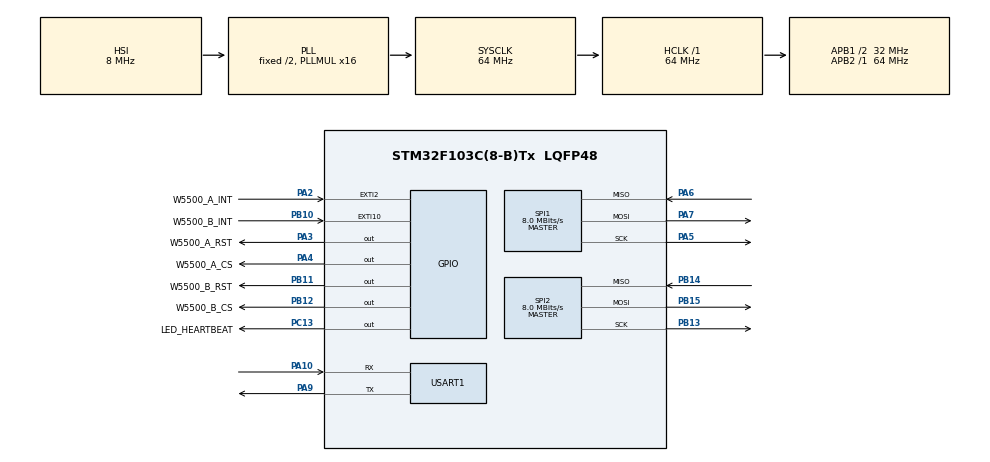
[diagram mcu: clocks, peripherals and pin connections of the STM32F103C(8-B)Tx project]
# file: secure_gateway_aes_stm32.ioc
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Dma.Request0=SPI1_RX
Dma.Request1=SPI1_TX
Dma.Request2=SPI2_RX
Dma.Request3=SPI2_TX
Dma.SPI1_RX.0.Direction=DMA_PERIPH_TO_MEMORY
Dma.SPI1_RX.0.Instance=DMA1_Channel2
Dma.SPI1_RX.0.MemDataAlignment=DMA_MDATAALIGN_BYTE
Dma.SPI1_RX.0.MemInc=DMA_MINC_ENABLE
Dma.SPI1_RX.0.Mode=DMA_NORMAL
Dma.SPI1_RX.0.PeriphDataAlignment=DMA_PDATAALIGN_BYTE
Dma.SPI1_RX.0.PeriphInc=DMA_PINC_DISABLE
Dma.SPI1_RX.0.Priority=DMA_PRIORITY_LOW
Dma.SPI1_TX.1.Direction=DMA_MEMORY_TO_PERIPH
Dma.SPI1_TX.1.Instance=DMA1_Channel3
Dma.SPI1_TX.1.MemDataAlignment=DMA_MDATAALIGN_BYTE
Dma.SPI1_TX.1.MemInc=DMA_MINC_ENABLE
Dma.SPI1_TX.1.Mode=DMA_NORMAL
Dma.SPI1_TX.1.PeriphDataAlignment=DMA_PDATAALIGN_BYTE
Dma.SPI1_TX.1.PeriphInc=DMA_PINC_DISABLE
Dma.SPI1_TX.1.Priority=DMA_PRIORITY_LOW
Dma.SPI2_RX.2.Direction=DMA_PERIPH_TO_MEMORY
Dma.SPI2_RX.2.Instance=DMA1_Channel4
Dma.SPI2_RX.2.MemDataAlignment=DMA_MDATAALIGN_BYTE
Dma.SPI2_RX.2.MemInc=DMA_MINC_ENABLE
Dma.SPI2_RX.2.Mode=DMA_NORMAL
Dma.SPI2_RX.2.PeriphDataAlignment=DMA_PDATAALIGN_BYTE
Dma.SPI2_RX.2.PeriphInc=DMA_PINC_DISABLE
Dma.SPI2_RX.2.Priority=DMA_PRIORITY_LOW
Dma.SPI2_TX.3.Direction=DMA_MEMORY_TO_PERIPH
Dma.SPI2_TX.3.Instance=DMA1_Channel5
Dma.SPI2_TX.3.MemDataAlignment=DMA_MDATAALIGN_BYTE
Dma.SPI2_TX.3.MemInc=DMA_MINC_ENABLE
Dma.SPI2_TX.3.Mode=DMA_NORMAL
Dma.SPI2_TX.3.PeriphDataAlignment=DMA_PDATAALIGN_BYTE
Dma.SPI2_TX.3.PeriphInc=DMA_PINC_DISABLE
Dma.SPI2_TX.3.Priority=DMA_PRIORITY_LOW
FREERTOS.INCLUDE_vTaskDelayUntil=1
FREERTOS.Tasks01=defaultTask,0,256,StartDefaultTask,Default,NULL,Dynamic,NULL,NULL
FREERTOS.configCHECK_FOR_STACK_OVERFLOW=2
FREERTOS.configMAX_PRIORITIES=6
FREERTOS.configUSE_COUNTING_SEMAPHORES=1
IWDG.Prescaler=IWDG_PRESCALER_16
IWDG.Reload=1249
Mcu.Family=STM32F1
Mcu.Name=STM32F103C(8-B)Tx
Mcu.Package=LQFP48
NVIC.DMA1_Channel2_IRQn=true\:6\:0\:true\:false\:true\:true\:false\:true\:true
NVIC.DMA1_Channel3_IRQn=true\:6\:0\:true\:false\:true\:true\:false\:true\:true
NVIC.DMA1_Channel4_IRQn=true\:6\:0\:true\:false\:true\:true\:false\:true\:true
NVIC.DMA1_Channel5_IRQn=true\:6\:0\:true\:false\:true\:true\:false\:true\:true
NVIC.EXTI15_10_IRQn=true\:6\:0\:true\:false\:true\:true\:true\:true\:true
NVIC.EXTI2_IRQn=true\:6\:0\:true\:false\:true\:true\:true\:true\:true
NVIC.PriorityGroup=NVIC_PRIORITYGROUP_4
NVIC.TIM4_IRQn=true\:15\:0\:false\:false\:true\:false\:false\:true\:true
NVIC.TimeBase=TIM4_IRQn
NVIC.TimeBaseIP=TIM4
PA10.Mode=Asynchronous
PA10.Signal=USART1_RX
PA13.Mode=Serial_Wire
PA13.Signal=SYS_JTMS-SWDIO
PA14.Mode=Serial_Wire
PA14.Signal=SYS_JTCK-SWCLK
PA2.GPIO_Label=W5500_A_INT
PA2.GPIO_ModeDefaultEXTI=GPIO_MODE_IT_FALLING
PA2.GPIO_PuPd=GPIO_PULLUP
PA2.Signal=GPXTI2
PA3.GPIO_Label=W5500_A_RST
PA3.PinState=GPIO_PIN_SET
PA3.Signal=GPIO_Output
PA4.GPIO_Label=W5500_A_CS
PA4.GPIO_Speed=GPIO_SPEED_FREQ_HIGH
PA4.PinState=GPIO_PIN_SET
PA4.Signal=GPIO_Output
PA5.Mode=Full_Duplex_Master
PA5.Signal=SPI1_SCK
PA6.Mode=Full_Duplex_Master
PA6.Signal=SPI1_MISO
PA7.Mode=Full_Duplex_Master
PA7.Signal=SPI1_MOSI
PA9.Mode=Asynchronous
PA9.Signal=USART1_TX
PB10.GPIO_Label=W5500_B_INT
PB10.GPIO_ModeDefaultEXTI=GPIO_MODE_IT_FALLING
PB10.GPIO_PuPd=GPIO_PULLUP
PB10.Signal=GPXTI10
PB11.GPIO_Label=W5500_B_RST
PB11.PinState=GPIO_PIN_SET
PB11.Signal=GPIO_Output
PB12.GPIO_Label=W5500_B_CS
PB12.GPIO_Speed=GPIO_SPEED_FREQ_HIGH
PB12.PinState=GPIO_PIN_SET
PB12.Signal=GPIO_Output
PB13.Mode=Full_Duplex_Master
PB13.Signal=SPI2_SCK
PB14.Mode=Full_Duplex_Master
PB14.Signal=SPI2_MISO
PB15.Mode=Full_Duplex_Master
PB15.Signal=SPI2_MOSI
PC13-TAMPER-RTC.GPIO_Label=LED_HEARTBEAT
PC13-TAMPER-RTC.PinState=GPIO_PIN_SET
PC13-TAMPER-RTC.Signal=GPIO_Output
ProjectManager.HeapSize=0x200
ProjectManager.StackSize=0x400
ProjectManager.TargetToolchain=STM32CubeIDE
RCC.AHBFreq_Value=64000000
RCC.APB1CLKDivider=RCC_HCLK_DIV2
RCC.APB1Freq_Value=32000000
RCC.APB1TimFreq_Value=64000000
RCC.APB2Freq_Value=64000000
RCC.APB2TimFreq_Value=64000000
RCC.HCLKFreq_Value=64000000
RCC.PLLMUL=RCC_PLL_MUL16
RCC.SYSCLKFreq_VALUE=64000000
RCC.SYSCLKSource=RCC_SYSCLKSOURCE_PLLCLK
RCC.USBFreq_Value=64000000
SPI1.BaudRatePrescaler=SPI_BAUDRATEPRESCALER_8
SPI1.CalculateBaudRate=8.0 MBits/s
SPI1.Direction=SPI_DIRECTION_2LINES
SPI1.Mode=SPI_MODE_MASTER
SPI1.VirtualType=VM_MASTER
SPI2.BaudRatePrescaler=SPI_BAUDRATEPRESCALER_4
SPI2.CalculateBaudRate=8.0 MBits/s
SPI2.Direction=SPI_DIRECTION_2LINES
SPI2.Mode=SPI_MODE_MASTER
SPI2.VirtualType=VM_MASTER
USART1.VirtualMode=VM_ASYNC
VP_FREERTOS_VS_CMSIS_V1.Mode=CMSIS_V1
VP_IWDG_VS_IWDG.Mode=IWDG_Activate
VP_SYS_VS_tim4.Mode=TIM4
board=custom

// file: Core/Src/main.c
/* USER CODE BEGIN Header */
/**
  ******************************************************************************
  * @file           : main.c
  * @brief          : Main program body
  ******************************************************************************
  * @attention
  *
  * Copyright (c) 2026 STMicroelectronics.
  * All rights reserved.
  *
  * This software is licensed under terms that can be found in the LICENSE file
  * in the root directory of this software component.
  * If no LICENSE file comes with this software, it is provided AS-IS.
  *
  ******************************************************************************
  */
/* USER CODE END Header */
#include "main.h"
#include "cmsis_os.h"
#include "dma.h"
#include "iwdg.h"
#include "spi.h"
#include "usart.h"
#include "gpio.h"

void SystemClock_Config(void);
void MX_FREERTOS_Init(void);

int main(void)
{

  /* MCU Configuration--------------------------------------------------------*/

  /* Reset of all peripherals, Initializes the Flash interface and the Systick. */
  HAL_Init();

  /* Configure the system clock */
  SystemClock_Config();

  /* Initialize all configured peripherals */
  MX_GPIO_Init();
  MX_DMA_Init();
  MX_SPI1_Init();
  MX_SPI2_Init();
  MX_USART1_UART_Init();
  MX_IWDG_Init();

  /* Call init function for freertos objects (in cmsis_os2.c) */
  MX_FREERTOS_Init();

  /* Start scheduler */
  osKernelStart();

  /* We should never get here as control is now taken by the scheduler */

  /* Infinite loop */
  while (1)
  {

  }
}

void SystemClock_Config(void)
{
  RCC_OscInitTypeDef RCC_OscInitStruct = {0};
  RCC_ClkInitTypeDef RCC_ClkInitStruct = {0};

  /** Initializes the RCC Oscillators according to the specified parameters
  * in the RCC_OscInitTypeDef structure.
  */
  RCC_OscInitStruct.OscillatorType = RCC_OSCILLATORTYPE_HSI|RCC_OSCILLATORTYPE_LSI;
  RCC_OscInitStruct.HSIState = RCC_HSI_ON;
  RCC_OscInitStruct.HSICalibrationValue = RCC_HSICALIBRATION_DEFAULT;
  RCC_OscInitStruct.LSIState = RCC_LSI_ON;
  RCC_OscInitStruct.PLL.PLLState = RCC_PLL_ON;
  RCC_OscInitStruct.PLL.PLLSource = RCC_PLLSOURCE_HSI_DIV2;
  RCC_OscInitStruct.PLL.PLLMUL = RCC_PLL_MUL16;
  if (HAL_RCC_OscConfig(&RCC_OscInitStruct) != HAL_OK)
  {
    Error_Handler();
  }

  /** Initializes the CPU, AHB and APB buses clocks
  */
  RCC_ClkInitStruct.ClockType = RCC_CLOCKTYPE_HCLK|RCC_CLOCKTYPE_SYSCLK
                              |RCC_CLOCKTYPE_PCLK1|RCC_CLOCKTYPE_PCLK2;
  RCC_ClkInitStruct.SYSCLKSource = RCC_SYSCLKSOURCE_PLLCLK;
  RCC_ClkInitStruct.AHBCLKDivider = RCC_SYSCLK_DIV1;
  RCC_ClkInitStruct.APB1CLKDivider = RCC_HCLK_DIV2;
  RCC_ClkInitStruct.APB2CLKDivider = RCC_HCLK_DIV1;

  if (HAL_RCC_ClockConfig(&RCC_ClkInitStruct, FLASH_LATENCY_2) != HAL_OK)
  {
    Error_Handler();
  }
}

void HAL_TIM_PeriodElapsedCallback(TIM_HandleTypeDef *htim)
{
  if (htim->Instance == TIM4)
  {
    HAL_IncTick();
  }
}

void Error_Handler(void)
{
  __disable_irq();
  while (1)
  {
  }
}

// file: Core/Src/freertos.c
/* USER CODE BEGIN Header */
/**
  ******************************************************************************
  * File Name          : freertos.c
  * Description        : Code for freertos applications
  ******************************************************************************
  * @attention
  *
  * Copyright (c) 2026 STMicroelectronics.
  * All rights reserved.
  *
  * This software is licensed under terms that can be found in the LICENSE file
  * in the root directory of this software component.
  * If no LICENSE file comes with this software, it is provided AS-IS.
  *
  ******************************************************************************
  */
/* USER CODE END Header */

#include "FreeRTOS.h"
#include "task.h"
#include "main.h"
#include "cmsis_os.h"

/* USER CODE BEGIN Includes */
#include "app_main.h"
#include "bsp_gpio.h"
#include "log_service.h"
#include <stdbool.h>
#include "bsp_w5500.h"
#include "net_service.h"
/* USER CODE END Includes */

osThreadId defaultTaskHandle;

void StartDefaultTask(void const * argument);

void MX_FREERTOS_Init(void); /* (MISRA C 2004 rule 8.1) */

/* GetIdleTaskMemory prototype (linked to static allocation support) */
void vApplicationGetIdleTaskMemory( StaticTask_t **ppxIdleTaskTCBBuffer, StackType_t **ppxIdleTaskStackBuffer, uint32_t *pulIdleTaskStackSize );

/* Hook prototypes */
void vApplicationStackOverflowHook(xTaskHandle xTask, signed char *pcTaskName);

/* USER CODE BEGIN 4 */
__weak void vApplicationStackOverflowHook(xTaskHandle xTask, signed char *pcTaskName)
{
   /* Run time stack overflow checking is performed if
   configCHECK_FOR_STACK_OVERFLOW is defined to 1 or 2. This hook function is
   called if a stack overflow is detected. */
    (void)xTask;
	(void)pcTaskName;
	taskDISABLE_INTERRUPTS();
	for (;;)
	{

	}
}
/* USER CODE END 4 */

/* USER CODE BEGIN GET_IDLE_TASK_MEMORY */
static StaticTask_t xIdleTaskTCBBuffer;
static StackType_t xIdleStack[configMINIMAL_STACK_SIZE];

void vApplicationGetIdleTaskMemory( StaticTask_t **ppxIdleTaskTCBBuffer, StackType_t **ppxIdleTaskStackBuffer, uint32_t *pulIdleTaskStackSize )
{
  *ppxIdleTaskTCBBuffer = &xIdleTaskTCBBuffer;
  *ppxIdleTaskStackBuffer = &xIdleStack[0];
  *pulIdleTaskStackSize = configMINIMAL_STACK_SIZE;
  /* place for user code */
}
/* USER CODE END GET_IDLE_TASK_MEMORY */

void MX_FREERTOS_Init(void) {

  /* Create the thread(s) */
  /* definition and creation of defaultTask */
  osThreadDef(defaultTask, StartDefaultTask, osPriorityNormal, 0, 256);
  defaultTaskHandle = osThreadCreate(osThread(defaultTask), NULL);

}

void StartDefaultTask(void const * argument)
{
  /* USER CODE BEGIN StartDefaultTask */
	/* Initialize entire Secure Gateway application:
	 * Configures W5500 SPI controllers, static network IP/ports,
	 * AES-128 crypto engine, static frame buffer pool, and launches
	 * all 5 dedicated FreeRTOS worker tasks (RxSpi1, RxSpi2, PacketProc, Tx, Heartbeat). */
	(void)app_main_init();

	/* Default startup task transitions to a low-frequency idle loop (1 second delay)
	 * leaving CPU execution time available for the higher-priority gateway tasks. */
	const TickType_t idle_delay_ticks = pdMS_TO_TICKS(1000U);

	/* Infinite loop */
	for (;;)
	{
	    vTaskDelay(idle_delay_ticks);
	}
  /* USER CODE END StartDefaultTask */
}
